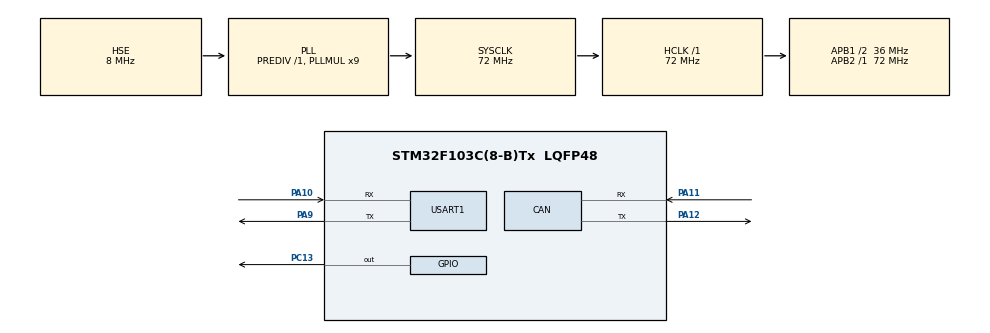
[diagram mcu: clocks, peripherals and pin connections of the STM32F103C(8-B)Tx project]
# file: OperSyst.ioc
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CAN.CalculateTimeBit=1333
CAN.CalculateTimeQuantum=444.44444444444446
FREERTOS.BinarySemaphores01=bISemSendSerialData,Dynamic,NULL;bISemGetCANData,Dynamic,NULL;bISemSendCANData,Dynamic,NULL;bISemGetSerialData,Dynamic,NULL
FREERTOS.Tasks01=defaultTask,0,128,StartDefaultTask,Default,NULL,Dynamic,NULL,NULL;serMonTask,0,128,SerialMonitor,Default,NULL,Dynamic,NULL,NULL;CANTask,2,128,CANKomunik,Default,NULL,Dynamic,NULL,NULL
FREERTOS.configTOTAL_HEAP_SIZE=6000
Mcu.Family=STM32F1
Mcu.Name=STM32F103C(8-B)Tx
Mcu.Package=LQFP48
Mcu.UserConstants=RELOAD_WDT_VALL,4096
NVIC.CAN1_RX1_IRQn=true\:6\:0\:true\:false\:true\:false
NVIC.CAN1_SCE_IRQn=true\:6\:0\:true\:false\:true\:false
NVIC.PriorityGroup=NVIC_PRIORITYGROUP_4
NVIC.TIM1_UP_IRQn=true\:0\:0\:false\:false\:true\:false
NVIC.TIM2_IRQn=true\:4\:0\:true\:false\:true\:false
NVIC.TIM3_IRQn=true\:4\:0\:true\:false\:true\:false
NVIC.TIM4_IRQn=true\:4\:0\:true\:false\:true\:false
NVIC.TimeBase=TIM1_UP_IRQn
NVIC.TimeBaseIP=TIM1
NVIC.USART1_IRQn=true\:3\:0\:true\:false\:true\:false
NVIC.USB_HP_CAN1_TX_IRQn=true\:6\:0\:true\:false\:true\:false
NVIC.USB_LP_CAN1_RX0_IRQn=true\:6\:0\:true\:false\:true\:false
PA10.Mode=Asynchronous
PA10.Signal=USART1_RX
PA11.Mode=Master
PA11.Signal=CAN_RX
PA12.Mode=Master
PA12.Signal=CAN_TX
PA13.Mode=Serial_Wire
PA13.Signal=SYS_JTMS-SWDIO
PA14.Mode=Serial_Wire
PA14.Signal=SYS_JTCK-SWCLK
PA9.Mode=Asynchronous
PA9.Signal=USART1_TX
PC13-TAMPER-RTC.PinState=GPIO_PIN_SET
PC13-TAMPER-RTC.Signal=GPIO_Output
PD0-OSC_IN.Mode=HSE-External-Oscillator
PD0-OSC_IN.Signal=RCC_OSC_IN
PD1-OSC_OUT.Mode=HSE-External-Oscillator
PD1-OSC_OUT.Signal=RCC_OSC_OUT
ProjectManager.HeapSize=0x200
ProjectManager.StackSize=0x400
ProjectManager.TargetToolchain=TrueSTUDIO
RCC.AHBFreq_Value=72000000
RCC.APB1CLKDivider=RCC_HCLK_DIV2
RCC.APB1Freq_Value=36000000
RCC.APB1TimFreq_Value=72000000
RCC.APB2Freq_Value=72000000
RCC.APB2TimFreq_Value=72000000
RCC.HCLKFreq_Value=72000000
RCC.PLLMUL=RCC_PLL_MUL9
RCC.PLLSourceVirtual=RCC_PLLSOURCE_HSE
RCC.SYSCLKFreq_VALUE=72000000
RCC.SYSCLKSource=RCC_SYSCLKSOURCE_PLLCLK
RCC.USBFreq_Value=72000000
TIM2.AutoReloadPreload=TIM_AUTORELOAD_PRELOAD_ENABLE
TIM2.Period=0xFFFA
TIM3.AutoReloadPreload=TIM_AUTORELOAD_PRELOAD_ENABLE
TIM3.ClockDivision=TIM_CLOCKDIVISION_DIV2
TIM3.Period=0xAAAA
TIM4.AutoReloadPreload=TIM_AUTORELOAD_PRELOAD_ENABLE
TIM4.ClockDivision=TIM_CLOCKDIVISION_DIV4
TIM4.Period=0x400
USART1.VirtualMode=VM_ASYNC
VP_FREERTOS_VS_ENABLE.Mode=Enabled
VP_SYS_VS_tim1.Mode=TIM1
VP_TIM2_VS_ClockSourceINT.Mode=Internal
VP_TIM2_VS_ClockSourceITR.Mode=TriggerSource_ITR2
VP_TIM2_VS_ControllerModeTrigger.Mode=Trigger Mode
VP_TIM3_VS_ClockSourceINT.Mode=Internal
VP_TIM3_VS_ClockSourceITR.Mode=TriggerSource_ITR3
VP_TIM3_VS_ControllerModeTrigger.Mode=Trigger Mode
VP_TIM4_VS_ClockSourceINT.Mode=Internal
VP_TIM4_VS_ClockSourceITR.Mode=TriggerSource_ITR1
VP_TIM4_VS_ControllerModeTrigger.Mode=Trigger Mode
board=OperSyst

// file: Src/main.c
/**
  ******************************************************************************
  * File Name          : main.c
  * Description        : Main program body
  ******************************************************************************
  * This notice applies to any and all portions of this file
  * that are not between comment pairs USER CODE BEGIN and
  * USER CODE END. Other portions of this file, whether
  * inserted by the user or by software development tools
  * are owned by their respective copyright owners.
  *
  * Copyright (c) 2018 STMicroelectronics International N.V.
  * All rights reserved.
  *
  * Redistribution and use in source and binary forms, with or without
  * modification, are permitted, provided that the following conditions are met:
  *
  * 1. Redistribution of source code must retain the above copyright notice,
  *    this list of conditions and the following disclaimer.
  * 2. Redistributions in binary form must reproduce the above copyright notice,
  *    this list of conditions and the following disclaimer in the documentation
  *    and/or other materials provided with the distribution.
  * 3. Neither the name of STMicroelectronics nor the names of other
  *    contributors to this software may be used to endorse or promote products
  *    derived from this software without specific written permission.
  * 4. This software, including modifications and/or derivative works of this
  *    software, must execute solely and exclusively on microcontroller or
  *    microprocessor devices manufactured by or for STMicroelectronics.
  * 5. Redistribution and use of this software other than as permitted under
  *    this license is void and will automatically terminate your rights under
  *    this license.
  *
  * THIS SOFTWARE IS PROVIDED BY STMICROELECTRONICS AND CONTRIBUTORS "AS IS"
  * AND ANY EXPRESS, IMPLIED OR STATUTORY WARRANTIES, INCLUDING, BUT NOT
  * LIMITED TO, THE IMPLIED WARRANTIES OF MERCHANTABILITY, FITNESS FOR A
  * PARTICULAR PURPOSE AND NON-INFRINGEMENT OF THIRD PARTY INTELLECTUAL PROPERTY
  * RIGHTS ARE DISCLAIMED TO THE FULLEST EXTENT PERMITTED BY LAW. IN NO EVENT
  * SHALL STMICROELECTRONICS OR CONTRIBUTORS BE LIABLE FOR ANY DIRECT, INDIRECT,
  * INCIDENTAL, SPECIAL, EXEMPLARY, OR CONSEQUENTIAL DAMAGES (INCLUDING, BUT NOT
  * LIMITED TO, PROCUREMENT OF SUBSTITUTE GOODS OR SERVICES; LOSS OF USE, DATA,
  * OR PROFITS; OR BUSINESS INTERRUPTION) HOWEVER CAUSED AND ON ANY THEORY OF
  * LIABILITY, WHETHER IN CONTRACT, STRICT LIABILITY, OR TORT (INCLUDING
  * NEGLIGENCE OR OTHERWISE) ARISING IN ANY WAY OUT OF THE USE OF THIS SOFTWARE,
  * EVEN IF ADVISED OF THE POSSIBILITY OF SUCH DAMAGE.
  *
  ******************************************************************************
  */
#include "main.h"
#include "stm32f1xx_hal.h"
#include "cmsis_os.h"

#include "serialPrint.h"

CAN_HandleTypeDef hcan;

TIM_HandleTypeDef htim2;
TIM_HandleTypeDef htim3;
TIM_HandleTypeDef htim4;

UART_HandleTypeDef huart1;

osThreadId defaultTaskHandle;
osThreadId serMonTaskHandle;
osThreadId CANTaskHandle;
osSemaphoreId bISemSendSerialDataHandle;
osSemaphoreId bISemGetCANDataHandle;
osSemaphoreId bISemSendCANDataHandle;
osSemaphoreId bISemGetSerialDataHandle;
osSemaphoreId xBinarySemaphoreHandle;
SemaphoreHandle_t xCountingSemaphore;

/* USER CODE BEGIN PV */
/* Private variables ---------------------------------------------------------*/

/* USER CODE END PV */

void SystemClock_Config(void);
static void MX_GPIO_Init(void);
static void MX_CAN_Init(void);
static void MX_TIM2_Init(void);
static void MX_TIM3_Init(void);
static void MX_TIM4_Init(void);
static void MX_USART1_UART_Init(void);
void StartDefaultTask(void const * argument);
void SerialMonitor(void const * argument);
void CANKomunik(void const * argument);
//void SetxBinarySemaphoreHandleFromISR( BaseType_t xHiPriorTaskWok);

/* USER CODE BEGIN PFP */
/* Private function prototypes -----------------------------------------------*/

/* USER CODE END PFP */

int main(void)
{

  /* MCU Configuration----------------------------------------------------------*/

  /* Reset of all peripherals, Initializes the Flash interface and the Systick. */
  HAL_Init();

  /* Configure the system clock */
  SystemClock_Config();

  /* Initialize all configured peripherals */
  MX_GPIO_Init();
  MX_CAN_Init();
  MX_TIM2_Init();
  MX_TIM3_Init();
  MX_TIM4_Init();
  MX_USART1_UART_Init();

  /* Create the semaphores(s) */
  /* definition and creation of bISemSendSerialData */
  osSemaphoreDef(bISemSendSerialData);
  bISemSendSerialDataHandle = osSemaphoreCreate(osSemaphore(bISemSendSerialData), 1);

  /* definition and creation of bISemGetCANData */
  osSemaphoreDef(bISemGetCANData);
  bISemGetCANDataHandle = osSemaphoreCreate(osSemaphore(bISemGetCANData), 1);

  /* definition and creation of bISemSendCANData */
  osSemaphoreDef(bISemSendCANData);
  bISemSendCANDataHandle = osSemaphoreCreate(osSemaphore(bISemSendCANData), 1);

  /* definition and creation of bISemGetSerialData */
  osSemaphoreDef(bISemGetSerialData);
  bISemGetSerialDataHandle = osSemaphoreCreate(osSemaphore(bISemGetSerialData), 1);

  osSemaphoreDef(xBinarySemaphore);
  xBinarySemaphoreHandle = osSemaphoreCreate(osSemaphore(xBinarySemaphore), 1);

  /* Create the thread(s) */
  /* definition and creation of defaultTask */
  osThreadDef(defaultTask, StartDefaultTask, osPriorityNormal, 0, 128);
  defaultTaskHandle = osThreadCreate(osThread(defaultTask), NULL);

  /* definition and creation of serMonTask */
  if( bISemGetSerialDataHandle != NULL )
  {
  osThreadDef(serMonTask, SerialMonitor, osPriorityNormal, 0, 128);
  serMonTaskHandle = osThreadCreate(osThread(serMonTask), NULL);
  }

  /* definition and creation of CANTask */
  osThreadDef(CANTask, CANKomunik, osPriorityNormal, 0, 128);
  CANTaskHandle = osThreadCreate(osThread(CANTask), NULL);

    /* Start scheduler */
  osKernelStart();
  /* We should never get here as control is now taken by the scheduler */

  /* Infinite loop */
  while (1)
  {

  }

}

/** System Clock Configuration
*/
void SystemClock_Config(void)
{

  RCC_OscInitTypeDef RCC_OscInitStruct;
  RCC_ClkInitTypeDef RCC_ClkInitStruct;

    /**Initializes the CPU, AHB and APB busses clocks
    */
  RCC_OscInitStruct.OscillatorType = RCC_OSCILLATORTYPE_HSE;
  RCC_OscInitStruct.HSEState = RCC_HSE_ON;
  RCC_OscInitStruct.HSEPredivValue = RCC_HSE_PREDIV_DIV1;
  RCC_OscInitStruct.HSIState = RCC_HSI_ON;
  RCC_OscInitStruct.PLL.PLLState = RCC_PLL_ON;
  RCC_OscInitStruct.PLL.PLLSource = RCC_PLLSOURCE_HSE;
  RCC_OscInitStruct.PLL.PLLMUL = RCC_PLL_MUL9;
  if (HAL_RCC_OscConfig(&RCC_OscInitStruct) != HAL_OK)
  {
    _Error_Handler(__FILE__, __LINE__);
  }

    /**Initializes the CPU, AHB and APB busses clocks
    */
  RCC_ClkInitStruct.ClockType = RCC_CLOCKTYPE_HCLK|RCC_CLOCKTYPE_SYSCLK
                              |RCC_CLOCKTYPE_PCLK1|RCC_CLOCKTYPE_PCLK2;
  RCC_ClkInitStruct.SYSCLKSource = RCC_SYSCLKSOURCE_PLLCLK;
  RCC_ClkInitStruct.AHBCLKDivider = RCC_SYSCLK_DIV1;
  RCC_ClkInitStruct.APB1CLKDivider = RCC_HCLK_DIV2;
  RCC_ClkInitStruct.APB2CLKDivider = RCC_HCLK_DIV1;

  if (HAL_RCC_ClockConfig(&RCC_ClkInitStruct, FLASH_LATENCY_2) != HAL_OK)
  {
    _Error_Handler(__FILE__, __LINE__);
  }

    /**Configure the Systick interrupt time
    */
  HAL_SYSTICK_Config(HAL_RCC_GetHCLKFreq()/1000);

    /**Configure the Systick
    */
  HAL_SYSTICK_CLKSourceConfig(SYSTICK_CLKSOURCE_HCLK);

  /* SysTick_IRQn interrupt configuration */
  HAL_NVIC_SetPriority(SysTick_IRQn, 15-1, 0);
}

/* CAN init function */
static void MX_CAN_Init(void)
{

  hcan.Instance = CAN1;
  hcan.Init.Prescaler = 16;
  hcan.Init.Mode = CAN_MODE_NORMAL;
  hcan.Init.SJW = CAN_SJW_1TQ;
  hcan.Init.BS1 = CAN_BS1_1TQ;
  hcan.Init.BS2 = CAN_BS2_1TQ;
  hcan.Init.TTCM = DISABLE;
  hcan.Init.ABOM = DISABLE;
  hcan.Init.AWUM = DISABLE;
  hcan.Init.NART = DISABLE;
  hcan.Init.RFLM = DISABLE;
  hcan.Init.TXFP = DISABLE;
  if (HAL_CAN_Init(&hcan) != HAL_OK)
  {
    _Error_Handler(__FILE__, __LINE__);
  }

}

/* TIM2 init function */
static void MX_TIM2_Init(void)
{

  TIM_ClockConfigTypeDef sClockSourceConfig;
  TIM_SlaveConfigTypeDef sSlaveConfig;
  TIM_MasterConfigTypeDef sMasterConfig;

  htim2.Instance = TIM2;
  htim2.Init.Prescaler = 36000;
  htim2.Init.CounterMode = TIM_COUNTERMODE_UP;
  htim2.Init.Period = 20000;
  htim2.Init.ClockDivision = TIM_CLOCKDIVISION_DIV1;
  htim2.Init.AutoReloadPreload = TIM_AUTORELOAD_PRELOAD_ENABLE;
  if (HAL_TIM_Base_Init(&htim2) != HAL_OK)
  {
    _Error_Handler(__FILE__, __LINE__);
  }

  sClockSourceConfig.ClockSource = TIM_CLOCKSOURCE_INTERNAL;
  if (HAL_TIM_ConfigClockSource(&htim2, &sClockSourceConfig) != HAL_OK)
  {
    _Error_Handler(__FILE__, __LINE__);
  }

  sSlaveConfig.SlaveMode = TIM_SLAVEMODE_TRIGGER;
  sSlaveConfig.InputTrigger = TIM_TS_ITR2;
  if (HAL_TIM_SlaveConfigSynchronization(&htim2, &sSlaveConfig) != HAL_OK)
  {
    _Error_Handler(__FILE__, __LINE__);
  }

  sMasterConfig.MasterOutputTrigger = TIM_TRGO_RESET;
  sMasterConfig.MasterSlaveMode = TIM_MASTERSLAVEMODE_DISABLE;
  if (HAL_TIMEx_MasterConfigSynchronization(&htim2, &sMasterConfig) != HAL_OK)
  {
    _Error_Handler(__FILE__, __LINE__);
  }

}

/* TIM3 init function */
static void MX_TIM3_Init(void)
{

  TIM_ClockConfigTypeDef sClockSourceConfig;
  TIM_SlaveConfigTypeDef sSlaveConfig;
  TIM_MasterConfigTypeDef sMasterConfig;

  htim3.Instance = TIM3;
  htim3.Init.Prescaler = 36000;
  htim3.Init.CounterMode = TIM_COUNTERMODE_UP;
  htim3.Init.Period = 2000;
  htim3.Init.ClockDivision = TIM_CLOCKDIVISION_DIV2;
  htim3.Init.AutoReloadPreload = TIM_AUTORELOAD_PRELOAD_ENABLE;
  if (HAL_TIM_Base_Init(&htim3) != HAL_OK)
  {
    _Error_Handler(__FILE__, __LINE__);
  }

  sClockSourceConfig.ClockSource = TIM_CLOCKSOURCE_INTERNAL;
  if (HAL_TIM_ConfigClockSource(&htim3, &sClockSourceConfig) != HAL_OK)
  {
    _Error_Handler(__FILE__, __LINE__);
  }

  sSlaveConfig.SlaveMode = TIM_SLAVEMODE_TRIGGER;
  sSlaveConfig.InputTrigger = TIM_TS_ITR3;
  if (HAL_TIM_SlaveConfigSynchronization(&htim3, &sSlaveConfig) != HAL_OK)
  {
    _Error_Handler(__FILE__, __LINE__);
  }

  sMasterConfig.MasterOutputTrigger = TIM_TRGO_RESET;
  sMasterConfig.MasterSlaveMode = TIM_MASTERSLAVEMODE_DISABLE;
  if (HAL_TIMEx_MasterConfigSynchronization(&htim3, &sMasterConfig) != HAL_OK)
  {
    _Error_Handler(__FILE__, __LINE__);
  }

}

/* TIM4 init function */
static void MX_TIM4_Init(void)
{

  TIM_ClockConfigTypeDef sClockSourceConfig;
  TIM_SlaveConfigTypeDef sSlaveConfig;
  TIM_MasterConfigTypeDef sMasterConfig;

  htim4.Instance = TIM4;
  htim4.Init.Prescaler = 0;
  htim4.Init.CounterMode = TIM_COUNTERMODE_UP;
  htim4.Init.Period = 0x400;
  htim4.Init.ClockDivision = TIM_CLOCKDIVISION_DIV4;
  htim4.Init.AutoReloadPreload = TIM_AUTORELOAD_PRELOAD_ENABLE;
  if (HAL_TIM_Base_Init(&htim4) != HAL_OK)
  {
    _Error_Handler(__FILE__, __LINE__);
  }

  sClockSourceConfig.ClockSource = TIM_CLOCKSOURCE_INTERNAL;
  if (HAL_TIM_ConfigClockSource(&htim4, &sClockSourceConfig) != HAL_OK)
  {
    _Error_Handler(__FILE__, __LINE__);
  }

  sSlaveConfig.SlaveMode = TIM_SLAVEMODE_TRIGGER;
  sSlaveConfig.InputTrigger = TIM_TS_ITR1;
  if (HAL_TIM_SlaveConfigSynchronization(&htim4, &sSlaveConfig) != HAL_OK)
  {
    _Error_Handler(__FILE__, __LINE__);
  }

  sMasterConfig.MasterOutputTrigger = TIM_TRGO_RESET;
  sMasterConfig.MasterSlaveMode = TIM_MASTERSLAVEMODE_DISABLE;
  if (HAL_TIMEx_MasterConfigSynchronization(&htim4, &sMasterConfig) != HAL_OK)
  {
    _Error_Handler(__FILE__, __LINE__);
  }

}

/* USART1 init function */
static void MX_USART1_UART_Init(void)
{

  huart1.Instance = USART1;
  huart1.Init.BaudRate = 115200;
  huart1.Init.WordLength = UART_WORDLENGTH_8B;
  huart1.Init.StopBits = UART_STOPBITS_1;
  huart1.Init.Parity = UART_PARITY_NONE;
  huart1.Init.Mode = UART_MODE_TX_RX;
  huart1.Init.HwFlowCtl = UART_HWCONTROL_NONE;
  huart1.Init.OverSampling = UART_OVERSAMPLING_16;
  if (HAL_UART_Init(&huart1) != HAL_OK)
  {
    _Error_Handler(__FILE__, __LINE__);
  }

}

/** Configure pins as
        * Analog
        * Input
        * Output
        * EVENT_OUT
        * EXTI
*/
static void MX_GPIO_Init(void)
{

  GPIO_InitTypeDef GPIO_InitStruct;

  /* GPIO Ports Clock Enable */
  __HAL_RCC_GPIOC_CLK_ENABLE();
  __HAL_RCC_GPIOD_CLK_ENABLE();
  __HAL_RCC_GPIOA_CLK_ENABLE();

  /*Configure GPIO pin Output Level */
  HAL_GPIO_WritePin(GPIOC, GPIO_PIN_13, GPIO_PIN_SET);

  /*Configure GPIO pin : PC13 */
  GPIO_InitStruct.Pin = GPIO_PIN_13;
  GPIO_InitStruct.Mode = GPIO_MODE_OUTPUT_PP;
  GPIO_InitStruct.Speed = GPIO_SPEED_FREQ_LOW;
  HAL_GPIO_Init(GPIOC, &GPIO_InitStruct);

}

/* StartDefaultTask function */
void StartDefaultTask(void const * argument)
{
  /* USER CODE BEGIN 5 */
  //xSemaphore = xSemaphoreCreateBinary();
  osDelay(100);
  HAL_TIM_Base_Start_IT(&htim2);
  HAL_TIM_Base_Start_IT(&htim3);
  /* Infinite loop */
  for(;;)
  {
	    osDelay(1);
  }
  /* USER CODE END 5 */
}

/* SerialMonitor function */
void SerialMonitor(void const * argument)
{
  /* USER CODE BEGIN SerialMonitor */
  /* Infinite loop */

	 BaseType_t xHigherPriorityTaskWoken;
	  xHigherPriorityTaskWoken = pdFALSE;
	  xSemaphoreTake ( xBinarySemaphoreHandle,1);

  for(;;)
  {
	    if (xSemaphoreTake ( xBinarySemaphoreHandle,portMAX_DELAY) == pdTRUE){
	    	clear();
	    	//osDelay(1000);
	    }
    	osDelay(1);
	    //	xSemaphoreGiveFromISR( xBinarySemaphoreHandle, xHigherPriorityTaskWoken);
  }
  /* USER CODE END SerialMonitor */
}

/* CANKomunik function */
void CANKomunik(void const * argument)
{
  for(;;)
  {
    osDelay(1);
  }
}

void HAL_TIM_PeriodElapsedCallback(TIM_HandleTypeDef *htim)
{
  if (htim->Instance == TIM1) {
    HAL_IncTick();
  }
}

void _Error_Handler(char * file, int line)
{
  while(1)
  {
  }
}

//void SetxBinarySemaphoreHandleFromISR(BaseType_t xHiPriorTaskWok)
//{
//  xSemaphoreGiveFromISR( xBinarySemaphoreHandle, xHiPriorTaskWok);
//}

/************************ (C) COPYRIGHT STMicroelectronics *****END OF FILE****/
